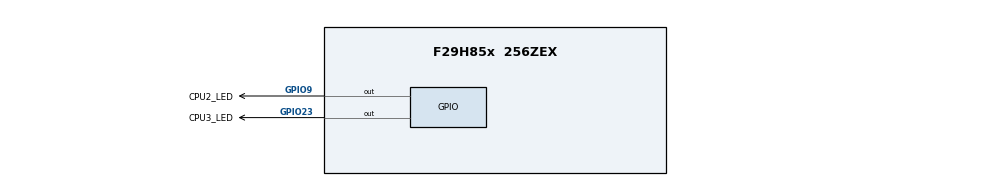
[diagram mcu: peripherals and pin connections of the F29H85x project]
/**
 * @cliArgs --device "F29H85x" --package "256ZEX" --part "F29H85x_256ZEX" --context "CPU1" --product "MCU_SDK_F29H85x@1.02.02.00"
 * @versions {"tool":"1.25.0+4237"}
 */

    
const divider15       = system.clockTree["PLL_REFDIV"];
divider15.divideValue = 1;

const multiplier1         = system.clockTree["PLL_IMULT"];
multiplier1.multiplyValue = 40;

const mux7       = system.clockTree["OSCCLKSRCSEL"];
mux7.inputSelect = "INTOSC2";

/**
 * Import the modules used in this configuration.
 */
const gpio  = scripting.addModule("/driverlib/gpio.js", {}, false);
const gpio1 = gpio.addInstance();
const gpio2 = gpio.addInstance();
const jtag  = scripting.addModule("/driverlib/jtag.js");
const sysctl = scripting.addModule("/driverlib/sysctl.js");

/**
 * Write custom configuration values to the imported modules.
 */

gpio1.$name          = "CPU2_LED";
gpio1.direction      = "GPIO_DIR_MODE_OUT";
gpio1.controllerCore = "GPIO_CORE_CPU2";
gpio1.gpioPin.$assign = "GPIO9";

gpio2.$name          = "CPU3_LED";
gpio2.direction      = "GPIO_DIR_MODE_OUT";
gpio2.controllerCore = "GPIO_CORE_CPU3";
gpio2.gpioPin.$assign = "GPIO23";

sysctl.LSConfig = "SplitLock";

/**
 * Pinmux solution for unlocked pins/peripherals. This ensures that minor changes to the automatic solver in a future
 * version of the tool will not impact the pinmux you originally saw.  These lines can be completely deleted in order to
 * re-solve from scratch.
 */
jtag.JTAG.$suggestSolution        = "JTAG";
jtag.JTAG.tdoPin.$suggestSolution = "GPIO223/TDO";
jtag.JTAG.tdiPin.$suggestSolution = "GPIO222/TDI";
